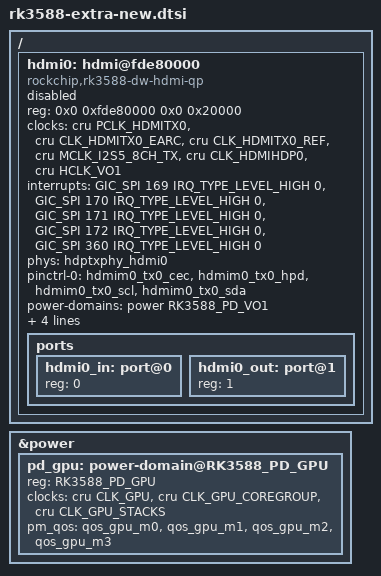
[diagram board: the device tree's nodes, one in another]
/ {
	hdmi0: hdmi@fde80000 {
		compatible = "rockchip,rk3588-dw-hdmi-qp";
		reg = <0x0 0xfde80000 0x0 0x20000>;
		clocks = <&cru PCLK_HDMITX0>,
			 <&cru CLK_HDMITX0_EARC>,
			 <&cru CLK_HDMITX0_REF>,
			 <&cru MCLK_I2S5_8CH_TX>,
			 <&cru CLK_HDMIHDP0>,
			 <&cru HCLK_VO1>;
		clock-names = "pclk", "earc", "ref", "aud", "hdp", "hclk_vo1";
		interrupts = <GIC_SPI 169 IRQ_TYPE_LEVEL_HIGH 0>,
			     <GIC_SPI 170 IRQ_TYPE_LEVEL_HIGH 0>,
			     <GIC_SPI 171 IRQ_TYPE_LEVEL_HIGH 0>,
			     <GIC_SPI 172 IRQ_TYPE_LEVEL_HIGH 0>,
			     <GIC_SPI 360 IRQ_TYPE_LEVEL_HIGH 0>;
		interrupt-names = "avp", "cec", "earc", "main", "hpd";
		phys = <&hdptxphy_hdmi0>;
		pinctrl-names = "default";
		pinctrl-0 = <&hdmim0_tx0_cec &hdmim0_tx0_hpd
			     &hdmim0_tx0_scl &hdmim0_tx0_sda>;
		power-domains = <&power RK3588_PD_VO1>;
		resets = <&cru SRST_HDMITX0_REF>, <&cru SRST_HDMIHDP0>;
		reset-names = "ref", "hdp";
		rockchip,grf = <&sys_grf>;
		rockchip,vo-grf = <&vo1_grf>;
		status = "disabled";

		ports {
			#address-cells = <1>;
			#size-cells = <0>;

			hdmi0_in: port@0 {
				reg = <0>;
			};

			hdmi0_out: port@1 {
				reg = <1>;
			};
		};
	};
};

&power {
	/delete-node/ power-domain@RK3588_PD_GPU;
	pd_gpu: power-domain@RK3588_PD_GPU {
		reg = <RK3588_PD_GPU>;
		clocks = <&cru CLK_GPU>,
			 <&cru CLK_GPU_COREGROUP>,
			 <&cru CLK_GPU_STACKS>;
		pm_qos = <&qos_gpu_m0>,
			 <&qos_gpu_m1>,
			 <&qos_gpu_m2>,
			 <&qos_gpu_m3>;
		#power-domain-cells = <0>;
	};
};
